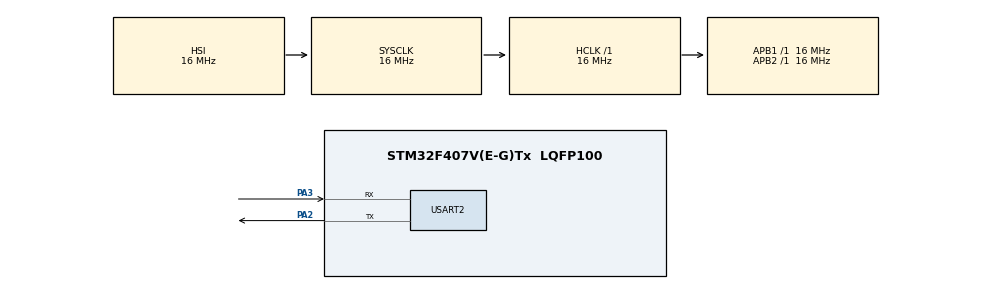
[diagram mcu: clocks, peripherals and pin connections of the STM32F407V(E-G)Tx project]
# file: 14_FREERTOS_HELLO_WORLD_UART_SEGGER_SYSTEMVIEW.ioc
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Mcu.Family=STM32F4
Mcu.Name=STM32F407V(E-G)Tx
Mcu.Package=LQFP100
NVIC.PriorityGroup=NVIC_PRIORITYGROUP_4
PA2.Mode=Asynchronous
PA2.Signal=USART2_TX
PA3.Mode=Asynchronous
PA3.Signal=USART2_RX
ProjectManager.HeapSize=0x200
ProjectManager.StackSize=0x400
ProjectManager.TargetToolchain=STM32CubeIDE
RCC.AHBFreq_Value=16000000
RCC.APB1Freq_Value=16000000
RCC.APB2Freq_Value=16000000
RCC.CortexFreq_Value=16000000
RCC.HSE_VALUE=25000000
RCC.HSI_VALUE=16000000
RCC.LSE_VALUE=32768
RCC.SYSCLKFreq_VALUE=16000000
RCC.VCOOutputFreq_Value=192000000
USART2.VirtualMode=VM_ASYNC
board=custom

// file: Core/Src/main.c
/* USER CODE BEGIN Header */
/**
  ******************************************************************************
  * @file           : main.c
  * @brief          : Main program body
  ******************************************************************************
  * @attention
  *
  * Copyright (c) 2022 STMicroelectronics.
  * All rights reserved.
  *
  * This software is licensed under terms that can be found in the LICENSE file
  * in the root directory of this software component.
  * If no LICENSE file comes with this software, it is provided AS-IS.
  *
  ******************************************************************************
  */
/* USER CODE END Header */
#include "main.h"

/* USER CODE BEGIN Includes */
#include "FreeRTOS.h"
#include "task.h"
#include "stdarg.h"
#include "stdio.h"
#include "string.h"
#include "stdbool.h"
/* USER CODE END Includes */

 UART_HandleTypeDef huart2;

/* USER CODE BEGIN PV */
TaskHandle_t myTask1Handle;
TaskHandle_t myTask2Handle;

bool UART_ACCSESS_KEY=1;

/* USER CODE END PV */

void SystemClock_Config(void);
static void MX_GPIO_Init(void);
static void MX_USART2_UART_Init(void);
/* USER CODE BEGIN PFP */
void printMessage(char *format, ...);
void myTask1(void *params);
void myTask2(void *params);
/* USER CODE END PFP */

int main(void)
{
  /* USER CODE BEGIN 1 */

  DWT->CTRL |= (1<<0);
  SEGGER_SYSVIEW_Conf();
  SEGGER_SYSVIEW_Start();

  /* USER CODE END 1 */

  /* MCU Configuration--------------------------------------------------------*/

  /* Reset of all peripherals, Initializes the Flash interface and the Systick. */
  HAL_Init();

  /* Configure the system clock */
  SystemClock_Config();

  /* Initialize all configured peripherals */
  MX_GPIO_Init();
  MX_USART2_UART_Init();
  /* USER CODE BEGIN 2 */

  xTaskCreate(myTask1, "myTask1", configMINIMAL_STACK_SIZE, NULL, 3, &myTask1Handle);
  xTaskCreate(myTask2, "myTask2"  , configMINIMAL_STACK_SIZE, NULL, 3, &myTask2Handle);
  vTaskStartScheduler();

  printMessage("Hello Here is FreeRtos HelloWorld Project");
  /* USER CODE END 2 */

  /* Infinite loop */
  while (1)
  {

  }
}

void SystemClock_Config(void)
{
  RCC_OscInitTypeDef RCC_OscInitStruct = {0};
  RCC_ClkInitTypeDef RCC_ClkInitStruct = {0};

  /** Configure the main internal regulator output voltage
  */
  __HAL_RCC_PWR_CLK_ENABLE();
  __HAL_PWR_VOLTAGESCALING_CONFIG(PWR_REGULATOR_VOLTAGE_SCALE1);

  /** Initializes the RCC Oscillators according to the specified parameters
  * in the RCC_OscInitTypeDef structure.
  */
  RCC_OscInitStruct.OscillatorType = RCC_OSCILLATORTYPE_HSI;
  RCC_OscInitStruct.HSIState = RCC_HSI_ON;
  RCC_OscInitStruct.HSICalibrationValue = RCC_HSICALIBRATION_DEFAULT;
  RCC_OscInitStruct.PLL.PLLState = RCC_PLL_NONE;
  if (HAL_RCC_OscConfig(&RCC_OscInitStruct) != HAL_OK)
  {
    Error_Handler();
  }

  /** Initializes the CPU, AHB and APB buses clocks
  */
  RCC_ClkInitStruct.ClockType = RCC_CLOCKTYPE_HCLK|RCC_CLOCKTYPE_SYSCLK
                              |RCC_CLOCKTYPE_PCLK1|RCC_CLOCKTYPE_PCLK2;
  RCC_ClkInitStruct.SYSCLKSource = RCC_SYSCLKSOURCE_HSI;
  RCC_ClkInitStruct.AHBCLKDivider = RCC_SYSCLK_DIV1;
  RCC_ClkInitStruct.APB1CLKDivider = RCC_HCLK_DIV1;
  RCC_ClkInitStruct.APB2CLKDivider = RCC_HCLK_DIV1;

  if (HAL_RCC_ClockConfig(&RCC_ClkInitStruct, FLASH_LATENCY_0) != HAL_OK)
  {
    Error_Handler();
  }
}

static void MX_USART2_UART_Init(void)
{

  huart2.Instance = USART2;
  huart2.Init.BaudRate = 115200;
  huart2.Init.WordLength = UART_WORDLENGTH_8B;
  huart2.Init.StopBits = UART_STOPBITS_1;
  huart2.Init.Parity = UART_PARITY_NONE;
  huart2.Init.Mode = UART_MODE_TX_RX;
  huart2.Init.HwFlowCtl = UART_HWCONTROL_NONE;
  huart2.Init.OverSampling = UART_OVERSAMPLING_16;
  if (HAL_UART_Init(&huart2) != HAL_OK)
  {
    Error_Handler();
  }

}

static void MX_GPIO_Init(void)
{

  /* GPIO Ports Clock Enable */
  __HAL_RCC_GPIOA_CLK_ENABLE();

}

/* USER CODE BEGIN 4 */
void myTask1(void *params)
{
	  while (1)
	  {
		  if(UART_ACCSESS_KEY==1)
		  {
			  UART_ACCSESS_KEY==0;
			  printMessage("Hello Here is Task1");
			  UART_ACCSESS_KEY==1;
			  taskYIELD();

		  }

	  }
}
void myTask2(void *params)
{
	  while (1)
	  {
		  if(UART_ACCSESS_KEY==1)
		  {
			  UART_ACCSESS_KEY==0;
			  printMessage("Hello Here is Task1");
			  UART_ACCSESS_KEY==1;
			  taskYIELD();

		  }
	  }
}

void printMessage(char *format, ...)
{
	char comingMessage[100];

	va_list vaList;
	va_start(vaList, format);
	vsprintf(comingMessage, format, vaList);
	HAL_UART_Transmit(&huart2, (uint8_t*)comingMessage, strlen(comingMessage), HAL_MAX_DELAY);
	va_end(vaList);
}

/* USER CODE END 4 */

void Error_Handler(void)
{
  __disable_irq();
  while (1)
  {
  }
}
